# HC32M413 register map
File version: 1.0
CPU: CM4 r0p1, little endian, MPU, FPU, 4 interrupt priority bits
Registers are 32-bit, read-write, reset 0x0 unless marked. A register's access mark holds for its fields unless they carry their own. Offsets are from the block's base; [hi:lo] are bit positions; {n}, {i} and the like mark numbered series; 'fields as' and 'values as' point back to an identical list.

## TMR4
Base 0x40017000
0x00 OCCR1UH 16-bit
0x02 OCCR2UH 16-bit
0x04 OCCR1UL 16-bit
0x06 OCCR2UL 16-bit
0x08 OCCR1VH 16-bit
0x0A OCCR2VH 16-bit
0x0C OCCR1VL 16-bit
0x0E OCCR2VL 16-bit
0x10 OCCR1WH 16-bit
0x12 OCCR2WH 16-bit
0x14 OCCR1WL 16-bit
0x16 OCCR2WL 16-bit
0x18 OCCR1XH 16-bit
0x1A OCCR2XH 16-bit
0x1C OCCR1XL 16-bit
0x1E OCCR2XL 16-bit
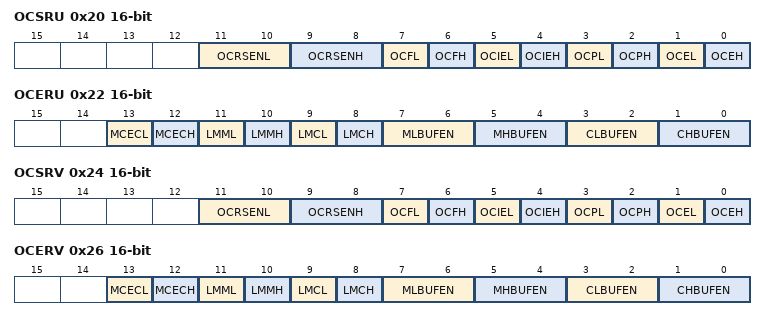
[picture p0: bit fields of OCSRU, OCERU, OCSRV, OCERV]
0x20 OCSRU 16-bit
  [11:10] OCRSENL, [9:8] OCRSENH, [7] OCFL, [6] OCFH, [5] OCIEL, [4] OCIEH, [3] OCPL, [2] OCPH, [1] OCEL, [0] OCEH
0x22 OCERU 16-bit
  [13] MCECL, [12] MCECH, [11] LMML, [10] LMMH, [9] LMCL, [8] LMCH, [7:6] MLBUFEN, [5:4] MHBUFEN, [3:2] CLBUFEN, [1:0] CHBUFEN
0x24 OCSRV 16-bit
  fields as OCSRU
0x26 OCERV 16-bit
  fields as OCERU
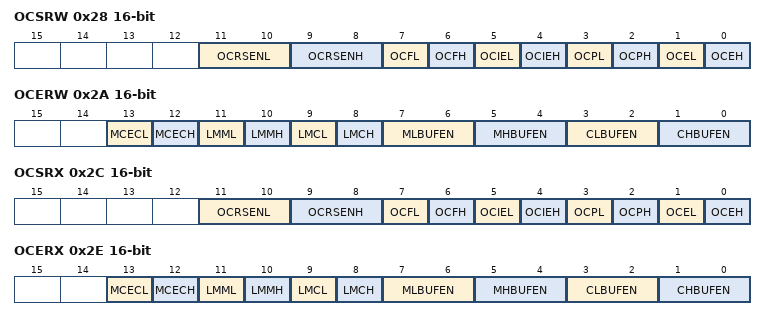
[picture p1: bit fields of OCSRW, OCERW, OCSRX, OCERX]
0x28 OCSRW 16-bit
  fields as OCSRU
0x2A OCERW 16-bit
  fields as OCERU
0x2C OCSRX 16-bit
  fields as OCSRU
0x2E OCERX 16-bit
  fields as OCERU
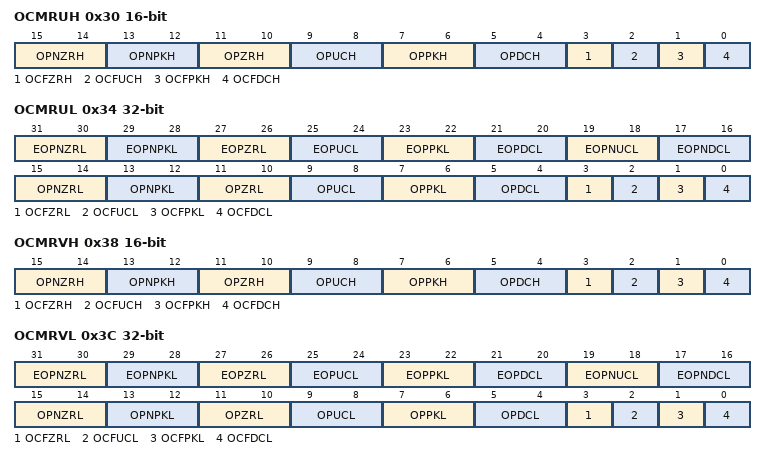
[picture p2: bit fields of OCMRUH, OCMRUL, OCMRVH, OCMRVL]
0x30 OCMRUH 16-bit
  [15:14] OPNZRH, [13:12] OPNPKH, [11:10] OPZRH, [9:8] OPUCH, [7:6] OPPKH, [5:4] OPDCH, [3] OCFZRH, [2] OCFUCH, [1] OCFPKH, [0] OCFDCH
0x34 OCMRUL
  [31:30] EOPNZRL, [29:28] EOPNPKL, [27:26] EOPZRL, [25:24] EOPUCL, [23:22] EOPPKL, [21:20] EOPDCL, [19:18] EOPNUCL, [17:16] EOPNDCL, [15:14] OPNZRL, [13:12] OPNPKL, [11:10] OPZRL, [9:8] OPUCL, [7:6] OPPKL, [5:4] OPDCL, [3] OCFZRL, [2] OCFUCL, [1] OCFPKL, [0] OCFDCL
0x38 OCMRVH 16-bit
  fields as OCMRUH
0x3C OCMRVL
  fields as OCMRUL
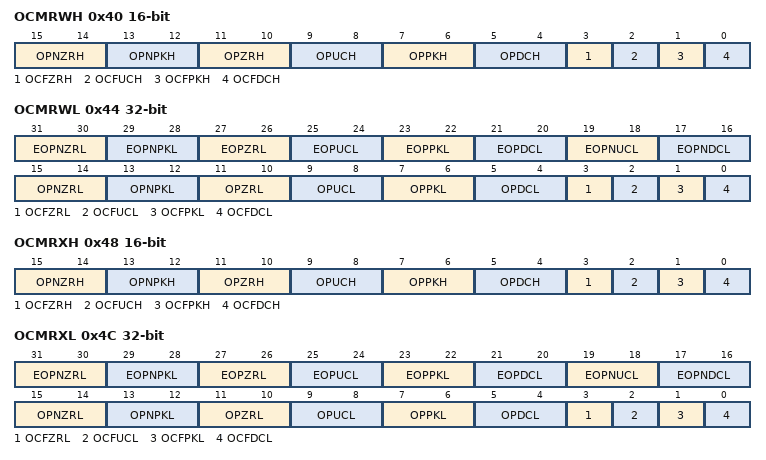
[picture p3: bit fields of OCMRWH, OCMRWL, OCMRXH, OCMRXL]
0x40 OCMRWH 16-bit
  fields as OCMRUH
0x44 OCMRWL
  fields as OCMRUL
0x48 OCMRXH 16-bit
  fields as OCMRUH
0x4C OCMRXL
  fields as OCMRUL
0x50 CPSR 16-bit reset 0xFFFF
0x54 CNTR 16-bit
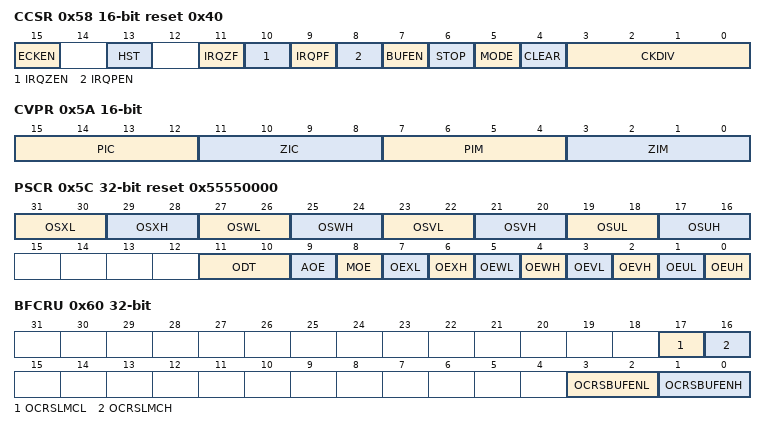
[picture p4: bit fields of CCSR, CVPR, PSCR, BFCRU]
0x58 CCSR 16-bit reset 0x40
  [15] ECKEN, [13] HST, [11] IRQZF, [10] IRQZEN, [9] IRQPF, [8] IRQPEN, [7] BUFEN, [6] STOP, [5] MODE, [4] CLEAR, [3:0] CKDIV
0x5A CVPR 16-bit
  [15:12] PIC ro, [11:8] ZIC ro, [7:4] PIM, [3:0] ZIM
0x5C PSCR reset 0x55550000
  [31:30] OSXL, [29:28] OSXH, [27:26] OSWL, [25:24] OSWH, [23:22] OSVL, [21:20] OSVH, [19:18] OSUL, [17:16] OSUH, [11:10] ODT, [9] AOE, [8] MOE, [7] OEXL, [6] OEXH, [5] OEWL, [4] OEWH, [3] OEVL, [2] OEVH, [1] OEUL, [0] OEUH
0x60 BFCRU
  [17] OCRSLMCL, [16] OCRSLMCH, [3:2] OCRSBUFENL, [1:0] OCRSBUFENH
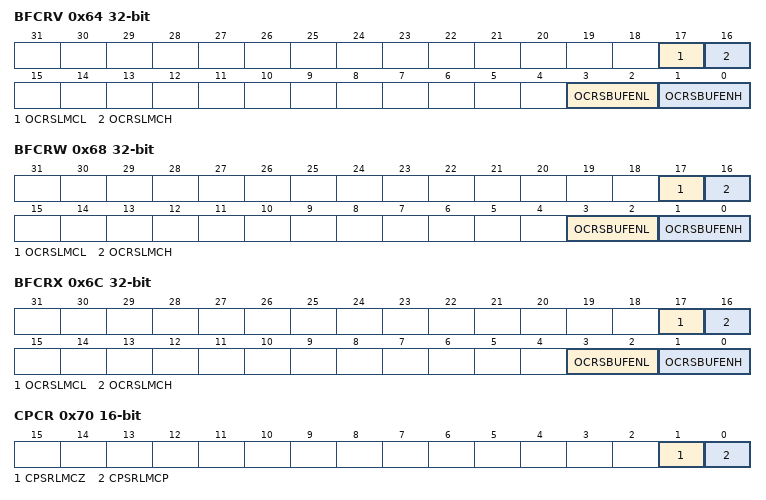
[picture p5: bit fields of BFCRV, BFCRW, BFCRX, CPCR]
0x64 BFCRV
  [17] OCRSLMCL, [16] OCRSLMCH, [3:2] OCRSBUFENL, [1:0] OCRSBUFENH
0x68 BFCRW
  [17] OCRSLMCL, [16] OCRSLMCH, [3:2] OCRSBUFENL, [1:0] OCRSBUFENH
0x6C BFCRX
  [17] OCRSLMCL, [16] OCRSLMCH, [3:2] OCRSBUFENL, [1:0] OCRSBUFENH
0x70 CPCR 16-bit
  [1] CPSRLMCZ, [0] CPSRLMCP
0x82 PFSRU 16-bit
0x84 PDARU 16-bit
0x86 PDBRU 16-bit
0x8A PFSRV 16-bit
0x8C PDARV 16-bit
0x8E PDBRV 16-bit
0x92 PFSRW 16-bit
0x94 PDARW 16-bit
0x96 PDBRW 16-bit
0x9A PFSRX 16-bit
0x9C PDARX 16-bit
0x9E PDBRX 16-bit
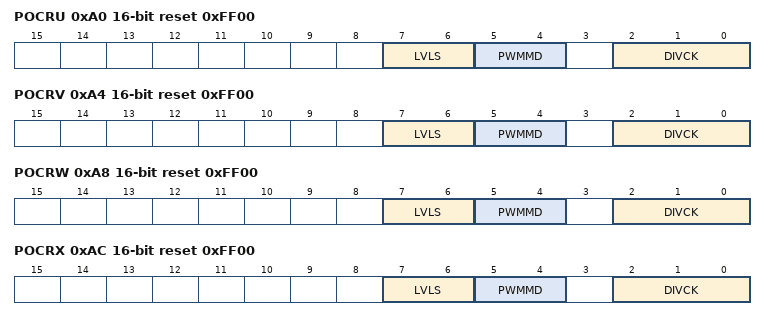
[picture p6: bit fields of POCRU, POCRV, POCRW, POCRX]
0xA0 POCRU 16-bit reset 0xFF00
  [7:6] LVLS, [5:4] PWMMD, [2:0] DIVCK
0xA4 POCRV 16-bit reset 0xFF00
  [7:6] LVLS, [5:4] PWMMD, [2:0] DIVCK
0xA8 POCRW 16-bit reset 0xFF00
  [7:6] LVLS, [5:4] PWMMD, [2:0] DIVCK
0xAC POCRX 16-bit reset 0xFF00
  [7:6] LVLS, [5:4] PWMMD, [2:0] DIVCK
0xB0 SCCRUH 16-bit
0xB4 SCCRUL 16-bit
0xB8 SCCRVH 16-bit
0xBC SCCRVL 16-bit
0xC0 SCCRWH 16-bit
0xC4 SCCRWL 16-bit
0xC8 SCCRXH 16-bit
0xCC SCCRXL 16-bit
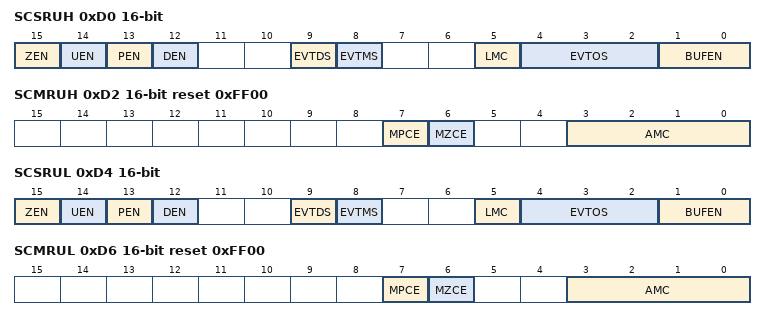
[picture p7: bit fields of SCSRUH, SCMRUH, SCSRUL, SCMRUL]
0xD0 SCSRUH 16-bit
  [15] ZEN, [14] UEN, [13] PEN, [12] DEN, [9] EVTDS, [8] EVTMS, [5] LMC, [4:2] EVTOS, [1:0] BUFEN
0xD2 SCMRUH 16-bit reset 0xFF00
  [7] MPCE, [6] MZCE, [3:0] AMC
0xD4 SCSRUL 16-bit
  fields as SCSRUH
0xD6 SCMRUL 16-bit reset 0xFF00
  [7] MPCE, [6] MZCE, [3:0] AMC
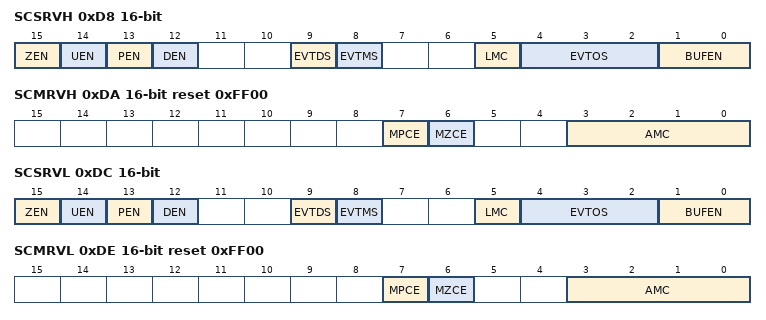
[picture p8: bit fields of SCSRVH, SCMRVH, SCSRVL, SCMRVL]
0xD8 SCSRVH 16-bit
  fields as SCSRUH
0xDA SCMRVH 16-bit reset 0xFF00
  [7] MPCE, [6] MZCE, [3:0] AMC
0xDC SCSRVL 16-bit
  fields as SCSRUH
0xDE SCMRVL 16-bit reset 0xFF00
  [7] MPCE, [6] MZCE, [3:0] AMC
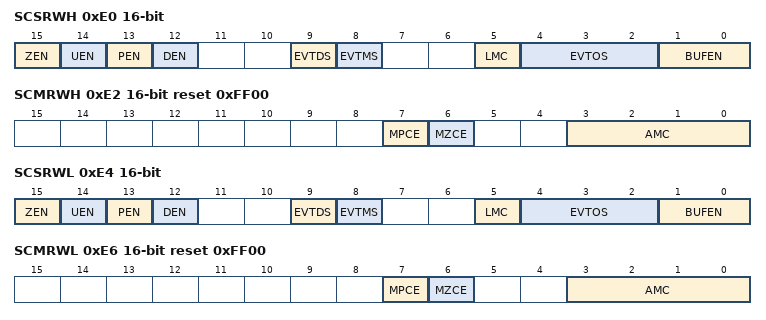
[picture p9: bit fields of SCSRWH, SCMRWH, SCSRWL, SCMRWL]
0xE0 SCSRWH 16-bit
  fields as SCSRUH
0xE2 SCMRWH 16-bit reset 0xFF00
  [7] MPCE, [6] MZCE, [3:0] AMC
0xE4 SCSRWL 16-bit
  fields as SCSRUH
0xE6 SCMRWL 16-bit reset 0xFF00
  [7] MPCE, [6] MZCE, [3:0] AMC
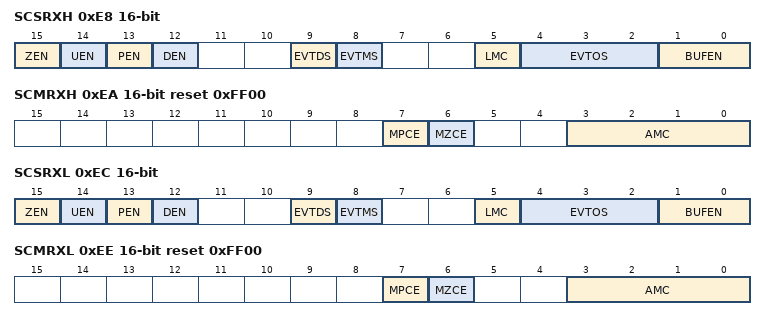
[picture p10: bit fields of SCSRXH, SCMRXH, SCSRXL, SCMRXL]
0xE8 SCSRXH 16-bit
  fields as SCSRUH
0xEA SCMRXH 16-bit reset 0xFF00
  [7] MPCE, [6] MZCE, [3:0] AMC
0xEC SCSRXL 16-bit
  fields as SCSRUH
0xEE SCMRXL 16-bit reset 0xFF00
  [7] MPCE, [6] MZCE, [3:0] AMC
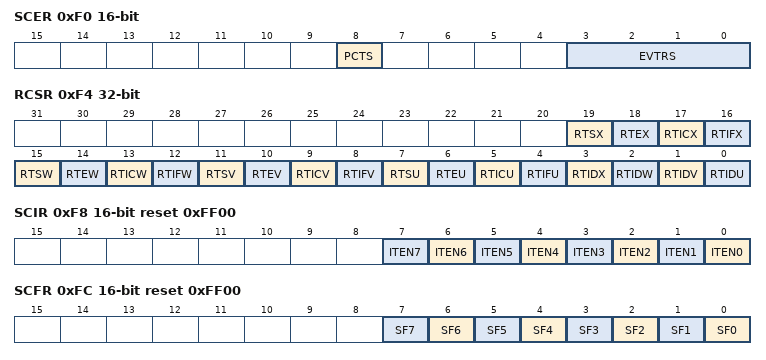
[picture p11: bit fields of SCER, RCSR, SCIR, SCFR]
0xF0 SCER 16-bit
  [8] PCTS, [3:0] EVTRS
0xF4 RCSR
  [19] RTSX, [18] RTEX, [17] RTICX, [16] RTIFX ro, [15] RTSW, [14] RTEW, [13] RTICW, [12] RTIFW ro, [11] RTSV, [10] RTEV, [9] RTICV, [8] RTIFV ro, [7] RTSU, [6] RTEU, [5] RTICU, [4] RTIFU ro, [3] RTIDX, [2] RTIDW, [1] RTIDV, [0] RTIDU
0xF8 SCIR 16-bit reset 0xFF00
  [n] ITEN{n} (n=0..7)
0xFC SCFR 16-bit reset 0xFF00
  [n] SF{n} (n=0..7)
0x100 OCCR3UH 16-bit
0x104 OCCR3UL 16-bit
0x108 OCCR3VH 16-bit
0x10C OCCR3VL 16-bit
0x110 OCCR3WH 16-bit
0x114 OCCR3WL 16-bit
0x118 OCCR3XH 16-bit
0x11C OCCR3XL 16-bit
